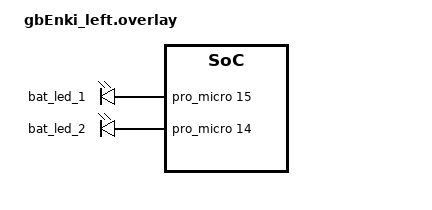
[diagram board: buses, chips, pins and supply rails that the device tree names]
/*
 * Copyright (c) 2020 Pete Johanson
 *
 * SPDX-License-Identifier: MIT
 */

#include "gbEnki.dtsi"

/ {
    leds {
        bat_led_1: led_b_1 {
            gpios = <&pro_micro 15 (GPIO_ACTIVE_HIGH | GPIO_PULL_DOWN)>;
        };
        bat_led_2: led_b_2 {
            gpios = <&pro_micro 14 (GPIO_ACTIVE_HIGH | GPIO_PULL_DOWN)>;
        };
    };
};

&kscan0 {
    col-gpios
        = <&pro_micro 21 GPIO_ACTIVE_HIGH>
        , <&pro_micro 20 GPIO_ACTIVE_HIGH>
        , <&pro_micro 19 GPIO_ACTIVE_HIGH>
        , <&pro_micro 18 GPIO_ACTIVE_HIGH>
        , <&pro_micro 15 GPIO_ACTIVE_HIGH>
        , <&pro_micro 14 GPIO_ACTIVE_HIGH>
        ;
};
